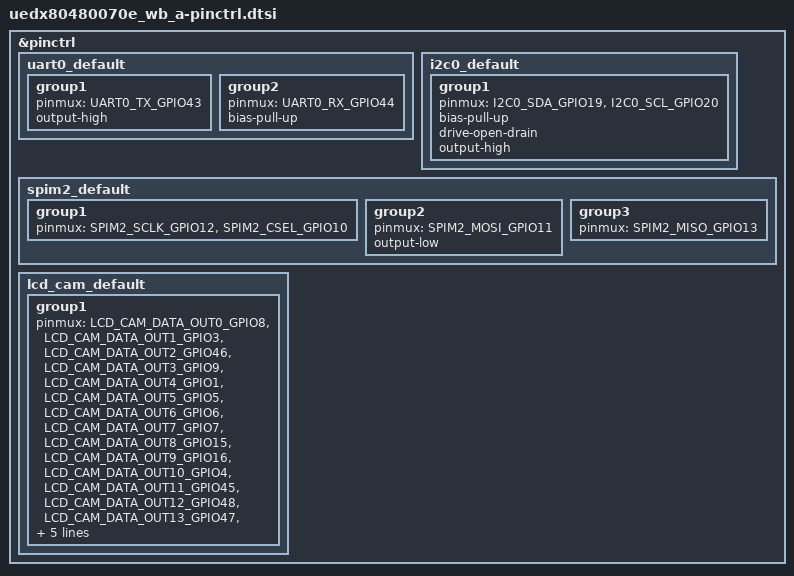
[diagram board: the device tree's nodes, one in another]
/*
 * SPDX-FileCopyrightText: Copyright The Zephyr Project Contributors
 * SPDX-License-Identifier: Apache-2.0
 */

#include <zephyr/dt-bindings/pinctrl/esp-pinctrl-common.h>
#include <zephyr/dt-bindings/pinctrl/esp32s3-pinctrl.h>
#include <zephyr/dt-bindings/pinctrl/esp32s3-gpio-sigmap.h>

&pinctrl {
	uart0_default: uart0_default {
		group1 {
			pinmux = <UART0_TX_GPIO43>;
			output-high;
		};

		group2 {
			pinmux = <UART0_RX_GPIO44>;
			bias-pull-up;
		};
	};

	i2c0_default: i2c0_default {
		group1 {
			pinmux = <I2C0_SDA_GPIO19>,
				 <I2C0_SCL_GPIO20>;
			bias-pull-up;
			drive-open-drain;
			output-high;
		};
	};

	spim2_default: spim2_default {
		group1 {
			pinmux = <SPIM2_SCLK_GPIO12>,
				 <SPIM2_CSEL_GPIO10>;
		};

		group2 {
			pinmux = <SPIM2_MOSI_GPIO11>;
			output-low;
		};

		group3 {
			pinmux = <SPIM2_MISO_GPIO13>;
		};
	};

	lcd_cam_default: lcd_cam_default {
		group1 {
			pinmux = <LCD_CAM_DATA_OUT0_GPIO8>,
				 <LCD_CAM_DATA_OUT1_GPIO3>,
				 <LCD_CAM_DATA_OUT2_GPIO46>,
				 <LCD_CAM_DATA_OUT3_GPIO9>,
				 <LCD_CAM_DATA_OUT4_GPIO1>,
				 <LCD_CAM_DATA_OUT5_GPIO5>,
				 <LCD_CAM_DATA_OUT6_GPIO6>,
				 <LCD_CAM_DATA_OUT7_GPIO7>,
				 <LCD_CAM_DATA_OUT8_GPIO15>,
				 <LCD_CAM_DATA_OUT9_GPIO16>,
				 <LCD_CAM_DATA_OUT10_GPIO4>,
				 <LCD_CAM_DATA_OUT11_GPIO45>,
				 <LCD_CAM_DATA_OUT12_GPIO48>,
				 <LCD_CAM_DATA_OUT13_GPIO47>,
				 <LCD_CAM_DATA_OUT14_GPIO21>,
				 <LCD_CAM_DATA_OUT15_GPIO14>,
				 <LCD_CAM_LCD_CLK_GPIO42>;
			output-enable;
			bias-disable;
		};
	};
};
